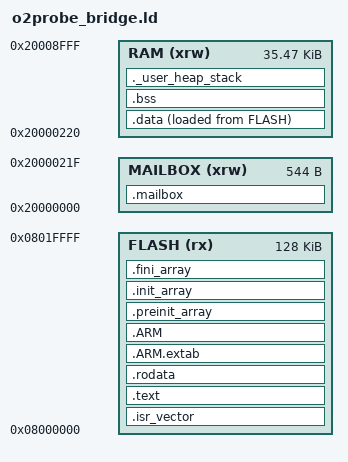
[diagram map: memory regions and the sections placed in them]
/* GENERATED-FROM: tool-ldscripts-ststm32 stm32g0/STM32G071CBTX_FLASH.ld
 *
 * The BENCH BRIDGE image (src/bridge_main.c). ST's stock script with one
 * change: the bottom 544 bytes of SRAM are carved out as MAILBOX, holding the
 * SWD host transport's fixed block (src/bridge_mailbox.h). NOLOAD, because
 * startup must neither load nor zero it - the firmware initialises it itself,
 * at a point it controls - and because the host writes a literal address that
 * the linker must not be free to move. tools/pio_image_check.py fails the
 * build if the symbol does not land on O2P_MBX_BASE.
 *
 * Otherwise it is the stock script on purpose. The bridge is the whole of the flash on
 * a board that is a bench adapter and nothing else: no bootloader below it, no
 * staging slot beside it, no descriptor, no configuration record. Carving this
 * part up is what the application and the bootloader do because they have to
 * coexist and survive a field update; a bridge has neither problem, and
 * pretending it does would put a second, wrong flash map in the tree.
 *
 * That also means a board flashed with this image no longer holds a probe.
 * Reflashing it as a probe is `pio run -e loader -t upload` followed by
 * `pio run -e o2probe -t upload`, both over SWD, exactly as a new board.
 */
/*
******************************************************************************
**
** @file        : LinkerScript.ld
**
** @author      : Auto-generated by STM32CubeIDE
**
** @brief       : Linker script for STM32G071CBTx Device from STM32G0 series
**                      128Kbytes FLASH
**                      36Kbytes RAM
**
**                Set heap size, stack size and stack location according
**                to application requirements.
**
**                Set memory bank area and size if external memory is used
**
**  Target      : STMicroelectronics STM32
**
**  Distribution: The file is distributed as is, without any warranty
**                of any kind.
**
******************************************************************************
** @attention
**
** <h2><center>&copy; Copyright (c) 2021 STMicroelectronics.
** All rights reserved.</center></h2>
**
** This software component is licensed by ST under BSD 3-Clause license,
** the "License"; You may not use this file except in compliance with the
** License. You may obtain a copy of the License at:
**                        opensource.org/licenses/BSD-3-Clause
**
******************************************************************************
*/

/* Entry Point */
ENTRY(Reset_Handler)

/* Highest address of the user mode stack */
_estack = ORIGIN(RAM) + LENGTH(RAM); /* end of "RAM" Ram type memory */

_Min_Heap_Size = 0x200; /* required amount of heap */
_Min_Stack_Size = 0x400; /* required amount of stack */

/* Memories definition */
MEMORY
{
  MAILBOX (xrw)   : ORIGIN = 0x20000000,   LENGTH = 0x220
  RAM     (xrw)   : ORIGIN = 0x20000000 + 0x220,   LENGTH = 36K - 0x220
  FLASH    (rx)   : ORIGIN = 0x08000000,   LENGTH = 128K
}

/* Sections */
SECTIONS
{
  /* The SWD host transport's block. Neither loaded nor zeroed by startup;
     o2p_mailbox_init() does that. See src/bridge_mailbox.h. */
  .mailbox (NOLOAD) :
  {
    . = ALIGN(8);
    KEEP(*(.mailbox))
    . = ALIGN(8);
  } >MAILBOX

  /* The startup code into "FLASH" Rom type memory */
  .isr_vector :
  {
    . = ALIGN(4);
    KEEP(*(.isr_vector)) /* Startup code */
    . = ALIGN(4);
  } >FLASH

  /* The program code and other data into "FLASH" Rom type memory */
  .text :
  {
    . = ALIGN(4);
    *(.text)           /* .text sections (code) */
    *(.text*)          /* .text* sections (code) */
    *(.glue_7)         /* glue arm to thumb code */
    *(.glue_7t)        /* glue thumb to arm code */
    *(.eh_frame)

    KEEP (*(.init))
    KEEP (*(.fini))

    . = ALIGN(4);
    _etext = .;        /* define a global symbols at end of code */
  } >FLASH

  /* Constant data into "FLASH" Rom type memory */
  .rodata :
  {
    . = ALIGN(4);
    *(.rodata)         /* .rodata sections (constants, strings, etc.) */
    *(.rodata*)        /* .rodata* sections (constants, strings, etc.) */
    . = ALIGN(4);
  } >FLASH

  .ARM.extab   : {
    . = ALIGN(4);
    *(.ARM.extab* .gnu.linkonce.armextab.*)
    . = ALIGN(4);
  } >FLASH

  .ARM : {
    . = ALIGN(4);
    __exidx_start = .;
    *(.ARM.exidx*)
    __exidx_end = .;
    . = ALIGN(4);
  } >FLASH

  .preinit_array     :
  {
    . = ALIGN(4);
    PROVIDE_HIDDEN (__preinit_array_start = .);
    KEEP (*(.preinit_array*))
    PROVIDE_HIDDEN (__preinit_array_end = .);
    . = ALIGN(4);
  } >FLASH

  .init_array :
  {
    . = ALIGN(4);
    PROVIDE_HIDDEN (__init_array_start = .);
    KEEP (*(SORT(.init_array.*)))
    KEEP (*(.init_array*))
    PROVIDE_HIDDEN (__init_array_end = .);
    . = ALIGN(4);
  } >FLASH

  .fini_array :
  {
    . = ALIGN(4);
    PROVIDE_HIDDEN (__fini_array_start = .);
    KEEP (*(SORT(.fini_array.*)))
    KEEP (*(.fini_array*))
    PROVIDE_HIDDEN (__fini_array_end = .);
    . = ALIGN(4);
  } >FLASH

  /* Used by the startup to initialize data */
  _sidata = LOADADDR(.data);

  /* Initialized data sections into "RAM" Ram type memory */
  .data :
  {
    . = ALIGN(4);
    _sdata = .;        /* create a global symbol at data start */
    *(.data)           /* .data sections */
    *(.data*)          /* .data* sections */
    *(.RamFunc)        /* .RamFunc sections */
    *(.RamFunc*)       /* .RamFunc* sections */

    . = ALIGN(4);
    _edata = .;        /* define a global symbol at data end */

  } >RAM AT> FLASH

  /* Uninitialized data section into "RAM" Ram type memory */
  . = ALIGN(4);
  .bss :
  {
    /* This is used by the startup in order to initialize the .bss section */
    _sbss = .;         /* define a global symbol at bss start */
    __bss_start__ = _sbss;
    *(.bss)
    *(.bss*)
    *(COMMON)

    . = ALIGN(4);
    _ebss = .;         /* define a global symbol at bss end */
    __bss_end__ = _ebss;
  } >RAM

  /* User_heap_stack section, used to check that there is enough "RAM" Ram  type memory left */
  ._user_heap_stack :
  {
    . = ALIGN(8);
    PROVIDE ( end = . );
    PROVIDE ( _end = . );
    . = . + _Min_Heap_Size;
    . = . + _Min_Stack_Size;
    . = ALIGN(8);
  } >RAM

  /* Remove information from the compiler libraries */
  /DISCARD/ :
  {
    libc.a ( * )
    libm.a ( * )
    libgcc.a ( * )
  }

  .ARM.attributes 0 : { *(.ARM.attributes) }
}
